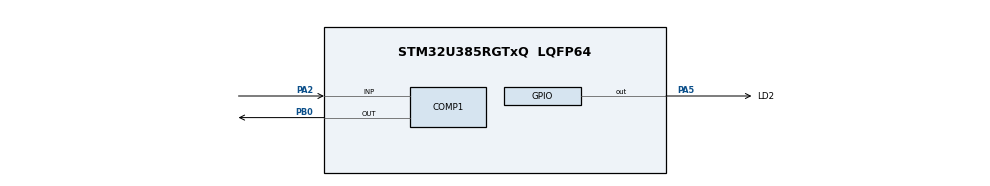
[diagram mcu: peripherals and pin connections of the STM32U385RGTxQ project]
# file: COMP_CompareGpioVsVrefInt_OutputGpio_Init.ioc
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COMP1.Hysteresis=COMP_HYSTERESIS_MEDIUM
CORTEX_M33_NS.userName=CORTEX_M33
Mcu.Family=STM32U3
Mcu.Name=STM32U385RGTxQ
Mcu.Package=LQFP64
NVIC.PriorityGroup=NVIC_PRIORITYGROUP_4
PA2.Mode=INP
PA2.Signal=COMP1_INP
PA5.GPIO_Label=LD2
PA5.Signal=GPIO_Output
PB0.Mode=ExternalOutput
PB0.Signal=COMP1_OUT
ProjectManager.HeapSize=0x200
ProjectManager.StackSize=0x400
ProjectManager.TargetToolchain=EWARM V9.20
RCC.ADCFreq_Value=96000000
RCC.AHBFreq_Value=96000000
RCC.APB1Freq_Value=96000000
RCC.APB1TimFreq_Value=96000000
RCC.APB2Freq_Value=96000000
RCC.APB2TimFreq_Value=96000000
RCC.APB3Freq_Value=96000000
RCC.CortexFreq_Value=12000000
RCC.HCLKFreq_Value=96000000
RCC.HSE_VALUE=16000000
RCC.HSI48_VALUE=48000000
RCC.HSI_VALUE=16000000
RCC.LSE_VALUE=32768
RCC.LSIDIV_VALUE=32000
RCC.MSISDIV=RCC_MSI_DIV1
RCC.SYSCLKFreq_VALUE=96000000
RCC.USBFreq_Value=96000000
VP_COMP1_VS_VREFINT.Mode=VREFINT
VP_ICACHE_VS_ICACHE.Mode=DirectMappedCache
VP_PWR_VS_DBSignals.Mode=DisableDeadBatterySignals
VP_PWR_VS_LPOM.Mode=PowerOptimisation
VP_PWR_VS_SECSignals.Mode=Security/Privilege
board=custom

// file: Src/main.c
/* USER CODE BEGIN Header */
/**
  ******************************************************************************
  * @file    Examples_LL/COMP/COMP_CompareGpioVsVrefInt_OutputGpio_Init/Src/main.c
  * @author  MCD Application Team
  * @brief   How to use a comparator peripheral to compare a voltage level
  *          on a GPIO pin versus the internal voltage reference (VrefInt)
  *          with comparator output connected to a GPIO pin.
  *          This example is based on the STM32U3xx COMP LL API;
  *          Peripheral initialization done using LL unitary services functions.
  ******************************************************************************
  * @attention
  *
  * Copyright (c) 2024 STMicroelectronics.
  * All rights reserved.
  *
  * This software is licensed under terms that can be found in the LICENSE file
  * in the root directory of this software component.
  * If no LICENSE file comes with this software, it is provided AS-IS.
  *
  ******************************************************************************
  */
/* USER CODE END Header */
#include "main.h"

void SystemClock_Config(void);
static void MX_GPIO_Init(void);
static void MX_COMP1_Init(void);
static void MX_ICACHE_Init(void);
/* USER CODE BEGIN PFP */

void Activate_COMP(void);
void LED_On(void);
void LED_Off(void);
void LED_Toggle(void);

/* USER CODE END PFP */

int main(void)
{

  /* MCU Configuration--------------------------------------------------------*/

  /* Reset of all peripherals, Initializes the Flash interface and the Systick. */

  /* System interrupt init*/
  NVIC_SetPriorityGrouping(NVIC_PRIORITYGROUP_4);

  /* SysTick_IRQn interrupt configuration */
  NVIC_SetPriority(SysTick_IRQn, NVIC_EncodePriority(NVIC_GetPriorityGrouping(),15, 0));

  /* Configure the system clock */
  SystemClock_Config();

  /* Initialize all configured peripherals */
  MX_GPIO_Init();
  MX_COMP1_Init();
  MX_ICACHE_Init();
  /* USER CODE BEGIN 2 */

  /* Activate comparator */
  Activate_COMP();

  /* Lock comparator instance */
  /* Note: Comparator lock is optional, to protect against any unexpected
           program action on comparator configuration
           (for example, due to program counter corruption). */
  //LL_COMP_Lock(COMP2);

  /* USER CODE END 2 */

  /* Infinite loop */
  /* USER CODE BEGIN WHILE */
  while (1)
  {
    /* Set LED state in function of state of GPIO connected to                */
    /* comparator output.                                                     */
    /* Note: State of GPIO is monitored for the purpose of this example.      */
    /*       An alternate solution is to monitor directly comparator output   */
    /*       using function "LL_COMP_ReadOutputLevel()".                      */
    if (LL_GPIO_IsInputPinSet(GPIOB, LL_GPIO_PIN_0) != 0)
    {
      LED_On();
    }
    else
    {
      LED_Off();
    }

    /* USER CODE END WHILE */

  }
}

void SystemClock_Config(void)
{
  /** Enable Epod Booster
  */
  LL_AHB1_GRP2_EnableClock(LL_AHB1_GRP2_PERIPH_PWR);
  LL_RCC_SetEPODBoosterClkSource(LL_RCC_EPODBOOSTCLKSRCE_MSIS);
  LL_RCC_SetEPODBoosterClkPrescaler(LL_RCC_EPODBOOSTCLKPRESCAL_1);
  LL_PWR_EnableEPODBooster();
  while(LL_PWR_IsActiveFlag_BOOST() != 1U)
  {
  }

  /** Configure the main internal regulator output voltage
  */
  LL_PWR_SetRegulVoltageScaling(LL_PWR_REGU_VOLTAGE_SCALE1);
  while(LL_PWR_GetRegulCurrentVOS() != LL_PWR_REGU_VOLTAGE_SCALE1)
  {
  }

  /** Set Flash latency before switching to MSIS
  */
  LL_FLASH_SetLatency(LL_FLASH_LATENCY_2);
  while(LL_FLASH_GetLatency() != LL_FLASH_LATENCY_2)
  {
  }

  /** Activate MSIS as source
  */
  LL_RCC_MSIS_SetClockSource(LL_RCC_MSIS_CLOCK_SOURCE_RC0);
  LL_RCC_MSIS_SetClockDivision(LL_RCC_MSIS_CLOCK_SOURCE_RC_DIV_1);
  LL_RCC_MSI_SetMSIxClockRange();
  LL_RCC_SetSysClkSource(LL_RCC_SYS_CLKSOURCE_MSIS);

  /** Wait till System clock is ready
  */
  while(LL_RCC_GetSysClkSource() != LL_RCC_SYS_CLKSOURCE_MSIS)
  {
  }

  LL_RCC_SetAHBPrescaler(LL_RCC_HCLK_SYSCLK_DIV_1);
  LL_RCC_SetAPB1Prescaler(LL_RCC_APB1_HCLK_DIV_1);
  LL_RCC_SetAPB2Prescaler(LL_RCC_APB2_HCLK_DIV_1);
  LL_RCC_SetAPB3Prescaler(LL_RCC_APB3_HCLK_DIV_1);

  LL_Init1msTick(96000000);

  LL_SetSystemCoreClock(96000000);
}

static void MX_COMP1_Init(void)
{

  LL_COMP_InitTypeDef COMP_InitStruct = {0};

  LL_GPIO_InitTypeDef GPIO_InitStruct = {0};

  /* Peripheral clock enable */
  LL_APB3_GRP1_EnableClock(LL_APB3_GRP1_PERIPH_COMP);

  LL_AHB2_GRP1_EnableClock(LL_AHB2_GRP1_PERIPH_GPIOA);
  LL_AHB2_GRP1_EnableClock(LL_AHB2_GRP1_PERIPH_GPIOB);
  /**COMP1 GPIO Configuration
  PA2   ------> COMP1_INP
  PB0   ------> COMP1_OUT
  */
  GPIO_InitStruct.Pin = LL_GPIO_PIN_2;
  GPIO_InitStruct.Mode = LL_GPIO_MODE_ANALOG;
  GPIO_InitStruct.Pull = LL_GPIO_PULL_NO;
  LL_GPIO_Init(GPIOA, &GPIO_InitStruct);

  GPIO_InitStruct.Pin = LL_GPIO_PIN_0;
  GPIO_InitStruct.Mode = LL_GPIO_MODE_ALTERNATE;
  GPIO_InitStruct.Speed = LL_GPIO_SPEED_FREQ_LOW;
  GPIO_InitStruct.OutputType = LL_GPIO_OUTPUT_PUSHPULL;
  GPIO_InitStruct.Pull = LL_GPIO_PULL_NO;
  GPIO_InitStruct.Alternate = LL_GPIO_AF_12;
  LL_GPIO_Init(GPIOB, &GPIO_InitStruct);

  COMP_InitStruct.InputPlus = LL_COMP_INPUT_PLUS_IO3;
  COMP_InitStruct.InputMinus = LL_COMP_INPUT_MINUS_VREFINT;
  COMP_InitStruct.InputHysteresis = LL_COMP_HYSTERESIS_MEDIUM;
  COMP_InitStruct.OutputPolarity = LL_COMP_OUTPUTPOL_NONINVERTED;
  COMP_InitStruct.OutputBlankingSource = LL_COMP_BLANKINGSRC_NONE;
  LL_COMP_Init(COMP1, &COMP_InitStruct);
  LL_COMP_SetPowerMode(COMP1, LL_COMP_POWERMODE_HIGHSPEED);

  /* Wait loop initialization and execution */
  /* Note: Variable divided by 2 to compensate partially CPU processing cycles */
  __IO uint32_t wait_loop_index = 0;
  wait_loop_index = (LL_COMP_DELAY_VOLTAGE_SCALER_STAB_US * (SystemCoreClock / (1000000 * 2)));
  while(wait_loop_index != 0)
  {
    wait_loop_index--;
  }
  LL_COMP_SetCommonWindowMode(__LL_COMP_COMMON_INSTANCE(COMP1), LL_COMP_WINDOWMODE_DISABLE);
  LL_COMP_SetCommonWindowOutput(__LL_COMP_COMMON_INSTANCE(COMP1), LL_COMP_WINDOWOUTPUT_EACH_COMP);
  LL_EXTI_DisableEvent_0_31(LL_EXTI_LINE_17);
  LL_EXTI_DisableIT_0_31(LL_EXTI_LINE_17);

}

static void MX_ICACHE_Init(void)
{

  /** Enable instruction cache in 1-way (direct mapped cache)
  */
  LL_ICACHE_SetMode(LL_ICACHE_1WAY);
  LL_ICACHE_Enable();

}

static void MX_GPIO_Init(void)
{
  LL_GPIO_InitTypeDef GPIO_InitStruct = {0};

  /* GPIO Ports Clock Enable */
  LL_AHB2_GRP1_EnableClock(LL_AHB2_GRP1_PERIPH_GPIOA);
  LL_AHB2_GRP1_EnableClock(LL_AHB2_GRP1_PERIPH_GPIOB);

  /**/
  LL_GPIO_ResetOutputPin(LD2_GPIO_Port, LD2_Pin);

  /**/
  GPIO_InitStruct.Pin = LD2_Pin;
  GPIO_InitStruct.Mode = LL_GPIO_MODE_OUTPUT;
  GPIO_InitStruct.Speed = LL_GPIO_SPEED_FREQ_LOW;
  GPIO_InitStruct.OutputType = LL_GPIO_OUTPUT_PUSHPULL;
  GPIO_InitStruct.Pull = LL_GPIO_PULL_NO;
  LL_GPIO_Init(LD2_GPIO_Port, &GPIO_InitStruct);

}

/* USER CODE BEGIN 4 */

/**
  * @brief  Perform comparator activation procedure
  *         (COMP instance: COMP2).
  * @param  None
  * @retval None
  */
void Activate_COMP(void)
{
  __IO uint32_t wait_loop_index = 0;

  /* Enable comparator */
  LL_COMP_Enable(COMP1);

  /* Delay for comparator startup time.                                       */
  /* Compute number of CPU cycles to wait for, from delay in us.              */
  /* Note: Variable divided by 2 to compensate partially                      */
  /*       CPU processing cycles (depends on compilation optimization).       */
  /* Note: If system clock frequency is below 200kHz, wait time will          */
  /*       correspond to the few CPU processing cycles to process this        */
  /*       calculation.                                                       */
  wait_loop_index = ((LL_COMP_DELAY_STARTUP_US * (SystemCoreClock / (100000 * 2))) / 10);
  while(wait_loop_index != 0)
  {
    wait_loop_index--;
  }
}

/**
  * @brief  Turn-on LD2.
  * @param  None
  * @retval None
  */
void LED_On(void)
{
  /* Turn LED on */
  LL_GPIO_SetOutputPin(LD2_GPIO_Port, LD2_Pin);
}

/**
  * @brief  Turn-off LD2.
  * @param  None
  * @retval None
  */
void LED_Off(void)
{
  /* Turn LED off */
  LL_GPIO_ResetOutputPin(LD2_GPIO_Port, LD2_Pin);
}

/**
  * @brief  Toggle LD2.
  * @param  None
  * @retval None
  */
void LED_Toggle(void)
{
  /* Turn LED off */
  LL_GPIO_TogglePin(LD2_GPIO_Port, LD2_Pin);
}

/* USER CODE END 4 */

void Error_Handler(void)
{
  /* USER CODE BEGIN Error_Handler_Debug */
  /* User can add his own implementation to report the HAL error return state */

  /* Turn on LED and remain in infinite loop */
  while (1)
  {
    LED_On();
  }
  /* USER CODE END Error_Handler_Debug */
}
